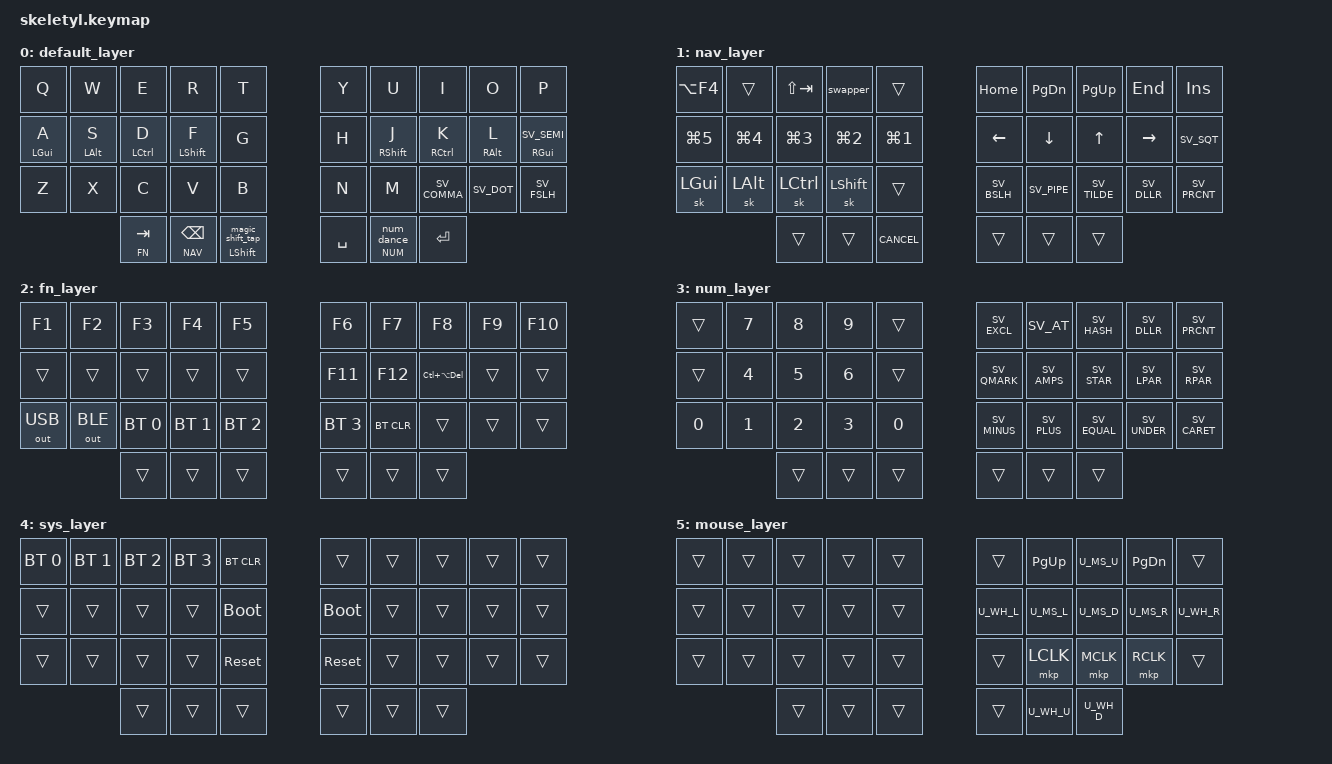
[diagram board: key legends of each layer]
#include <behaviors.dtsi>
#include <dt-bindings/zmk/bt.h>
#include <dt-bindings/zmk/keys.h>
#include <dt-bindings/zmk/outputs.h>

/* Key position labels (LT0..LH2/RH2 etc) */
#include <zmk-helpers/key-labels/36.h>

/* Swedish symbol macros (SV_*) */
#include "keys_sv.h"

/* urob modules */
#include <behaviors/unicode.dtsi>
#include <behaviors/num_word.dtsi>

/* Local split-out config */
#include "mouse.dtsi"
#include "leader.dtsi"

#define DEF 0
#define NAV 1
#define FN  2
#define NUM 3
#define SYS 4
#define MOUSE 5

#define ___ &trans
#define XXX &none

/* Homerow mod position groups (used for hold-trigger-key-positions) */
#define KEYS_L LT0 LT1 LT2 LT3 LT4 LM0 LM1 LM2 LM3 LM4 LB0 LB1 LB2 LB3 LB4
#define KEYS_R RT0 RT1 RT2 RT3 RT4 RM0 RM1 RM2 RM3 RM4 RB0 RB1 RB2 RB3 RB4
#define THUMBS LH2 LH1 LH0 RH0 RH1 RH2

/* Global tweaks (urob-style) */
&sk {
  release-after-ms = <900>;
  quick-release;
};

&sl {
  ignore-modifiers;
};

&lt {
  flavor = "balanced";
  tapping-term-ms = <200>;
  quick-tap-ms = <175>;
};

/* Unicode defaults: macOS is the most likely given your host machine */
&uc {
  default-mode = <UC_MODE_MACOS>;
};

/ {
  behaviors {
    /* Timeless HRMs (balanced + positional hold-tap, trigger on release) */
    hml: hml {
      compatible = "zmk,behavior-hold-tap";
      label = "HML";
      #binding-cells = <2>;
      flavor = "balanced";
      tapping-term-ms = <280>;
      quick-tap-ms = <175>;
      require-prior-idle-ms = <150>;
      bindings = <&kp>, <&kp>;
      hold-trigger-key-positions = <KEYS_R THUMBS>;
      hold-trigger-on-release;
    };

    hmr: hmr {
      compatible = "zmk,behavior-hold-tap";
      label = "HMR";
      #binding-cells = <2>;
      flavor = "balanced";
      tapping-term-ms = <280>;
      quick-tap-ms = <175>;
      require-prior-idle-ms = <150>;
      bindings = <&kp>, <&kp>;
      hold-trigger-key-positions = <KEYS_L THUMBS>;
      hold-trigger-on-release;
    };

    /* Tri-state swapper (Alt-Tab) */
    swapper: swapper {
      compatible = "zmk,behavior-tri-state";
      label = "SWAPPER";
      #binding-cells = <0>;
      bindings = <&kt LALT>, <&kp TAB>, <&kt LALT>;
      ignored-layers = <NAV>;
    };

    /* Smart mouse toggle (tri-state): turns off on left-hand key press */
    smart_mouse: smart_mouse {
      compatible = "zmk,behavior-tri-state";
      label = "SMART_MOUSE";
      #binding-cells = <0>;
      bindings = <&tog MOUSE>, <&none>, <&tog MOUSE>;
      ignored-key-positions = <LT1 LT2 KEYS_R THUMBS>;
      ignored-layers = <MOUSE>;
    };

    /* Shift-repeat (adaptive key): repeat after any alpha */
    shift_repeat: shift_repeat {
      compatible = "zmk,behavior-adaptive-key";
      label = "SHIFT_REPEAT";
      #binding-cells = <0>;
      bindings = <&sk LSHFT>;

      repeat {
        trigger-keys = <A B C D E F G H I J K L M N O P Q R S T U V W X Y Z>;
        bindings = <&key_repeat>;
        max-prior-idle-ms = <1200>;
        strict-modifiers;
      };
    };

    /* Magic shift: tap = repeat/sticky-shift, shifted tap = caps-word, hold = shift */
    magic_shift_tap: magic_shift_tap {
      compatible = "zmk,behavior-mod-morph";
      label = "MAGIC_SHIFT_TAP";
      #binding-cells = <0>;
      bindings = <&shift_repeat>, <&caps_word>;
      mods = <(MOD_LSFT)>;
    };

    magic_shift: magic_shift {
      compatible = "zmk,behavior-hold-tap";
      label = "MAGIC_SHIFT";
      #binding-cells = <2>;
      flavor = "balanced";
      tapping-term-ms = <200>;
      quick-tap-ms = <175>;
      bindings = <&kp>, <&magic_shift_tap>;
    };

    /* Smart num: tap = num-word, double-tap = sticky NUM, hold = momentary NUM */
    num_dance: num_dance {
      compatible = "zmk,behavior-tap-dance";
      label = "NUM_DANCE";
      #binding-cells = <0>;
      tapping-term-ms = <200>;
      bindings = <&num_word NUM>, <&sl NUM>;
    };

    smart_num: smart_num {
      compatible = "zmk,behavior-hold-tap";
      label = "SMART_NUM";
      #binding-cells = <2>;
      flavor = "balanced";
      tapping-term-ms = <200>;
      quick-tap-ms = <175>;
      bindings = <&mo>, <&num_dance>;
    };

    /* Tap: bspc | Shift+tap: del */
    bs_del: bs_del {
      compatible = "zmk,behavior-mod-morph";
      label = "BS_DEL";
      #binding-cells = <0>;
      bindings = <&kp BSPC>, <&kp DEL>;
      mods = <(MOD_LSFT|MOD_RSFT)>;
    };

    /* Paren combos: tap = () | Shift+tap = <> */
    lpar_lt: lpar_lt {
      compatible = "zmk,behavior-mod-morph";
      label = "LPAR_LT";
      #binding-cells = <0>;
      bindings = <&kp SV_LPAR>, <&kp SV_LT>;
      mods = <(MOD_LSFT|MOD_RSFT)>;
    };

    rpar_gt: rpar_gt {
      compatible = "zmk,behavior-mod-morph";
      label = "RPAR_GT";
      #binding-cells = <0>;
      bindings = <&kp SV_RPAR>, <&kp SV_GT>;
      mods = <(MOD_LSFT|MOD_RSFT)>;
    };

    /* Tap: SPACE | Hold: NAV */
    lt_spc: lt_spc {
      compatible = "zmk,behavior-hold-tap";
      label = "LT_SPC";
      #binding-cells = <2>;
      flavor = "balanced";
      tapping-term-ms = <200>;
      quick-tap-ms = <175>;
      bindings = <&mo>, <&kp>;
    };

    /* Sticky shift + leader */
    leader_sft: leader_sft {
      compatible = "zmk,behavior-macro";
      label = "LEADER_SFT";
      #binding-cells = <0>;
      wait-ms = <0>;
      tap-ms = <5>;
      bindings = <&sk LSHFT &leader>;
    };
  };

  keymap {
    compatible = "zmk,keymap";

    default_layer {
      bindings = <
        &kp Q          &kp W          &kp E          &kp R          &kp T                &kp Y          &kp U          &kp I          &kp O          &kp P
        &hml LGUI A    &hml LALT S    &hml LCTRL D   &hml LSHFT F   &kp G                &kp H          &hmr RSHFT J    &hmr RCTRL K    &hmr RALT L     &hmr RGUI SV_SEMI
        &kp Z          &kp X          &kp C          &kp V          &kp B                &kp N          &kp M          &kp SV_COMMA    &kp SV_DOT      &kp SV_FSLH
                                     &lt FN TAB      &lt NAV BSPC   &magic_shift LSHFT 0         &kp SPACE        &smart_num NUM 0  &kp RET
      >;
    };

    nav_layer {
      bindings = <
        &kp LA(F4)     ___            &kp LS(TAB)    &swapper        ___                 &kp HOME        &kp PG_DN       &kp PG_UP      &kp END         &kp INS
        &kp LG(N5)     &kp LG(N4)     &kp LG(N3)     &kp LG(N2)      &kp LG(N1)          &kp LEFT        &kp DOWN        &kp UP         &kp RIGHT       &kp SV_SQT
        &sk LGUI       &sk LALT       &sk LCTRL      &sk LSHFT       ___                 &kp SV_BSLH     &kp SV_PIPE     &kp SV_TILDE   &kp SV_DLLR     &kp SV_PRCNT
                                     ___            ___             &kp K_CANCEL        ___            ___            ___
      >;
    };

    fn_layer {
      bindings = <
        &kp F1         &kp F2         &kp F3         &kp F4          &kp F5              &kp F6         &kp F7         &kp F8         &kp F9         &kp F10
      ___            ___            ___            ___             ___                 &kp F11        &kp F12        &kp LC(LA(DEL)) ___            ___
        &out OUT_USB   &out OUT_BLE   &bt BT_SEL 0   &bt BT_SEL 1    &bt BT_SEL 2        &bt BT_SEL 3   &bt BT_CLR     ___            ___            ___
                                     ___            ___             ___                 ___            ___            ___
      >;
    };

    num_layer {
      bindings = <
        ___            &kp N7         &kp N8         &kp N9          ___                 &kp SV_EXCL    &kp SV_AT      &kp SV_HASH    &kp SV_DLLR    &kp SV_PRCNT
        ___            &kp N4         &kp N5         &kp N6          ___                 &kp SV_QMARK   &kp SV_AMPS    &kp SV_STAR    &kp SV_LPAR    &kp SV_RPAR
        &kp N0         &kp N1         &kp N2         &kp N3          &kp N0              &kp SV_MINUS   &kp SV_PLUS    &kp SV_EQUAL   &kp SV_UNDER   &kp SV_CARET
                                     ___            ___             ___                 ___            ___            ___
      >;
    };

    sys_layer {
      bindings = <
        &bt BT_SEL 0   &bt BT_SEL 1   &bt BT_SEL 2   &bt BT_SEL 3    &bt BT_CLR          ___            ___            ___            ___            ___
        ___            ___            ___            ___             &bootloader         &bootloader    ___            ___            ___            ___
        ___            ___            ___            ___             &sys_reset          &sys_reset     ___            ___            ___            ___
                                     ___            ___             ___                 ___            ___            ___
      >;
    };

    mouse_layer {
      bindings = <
        ___            ___            ___            ___             ___                 ___            &kp PG_UP      U_MS_U         &kp PG_DN      ___
        ___            ___            ___            ___             ___                 U_WH_L         U_MS_L         U_MS_D         U_MS_R         U_WH_R
        ___            ___            ___            ___             ___                 ___            &mkp LCLK      &mkp MCLK      &mkp RCLK      ___
                                     ___            ___             ___                 ___            U_WH_U         U_WH_D
      >;
    };
  };
};

/* Combos must come after layer constants + behaviors are defined */
#include "combos.dtsi"
